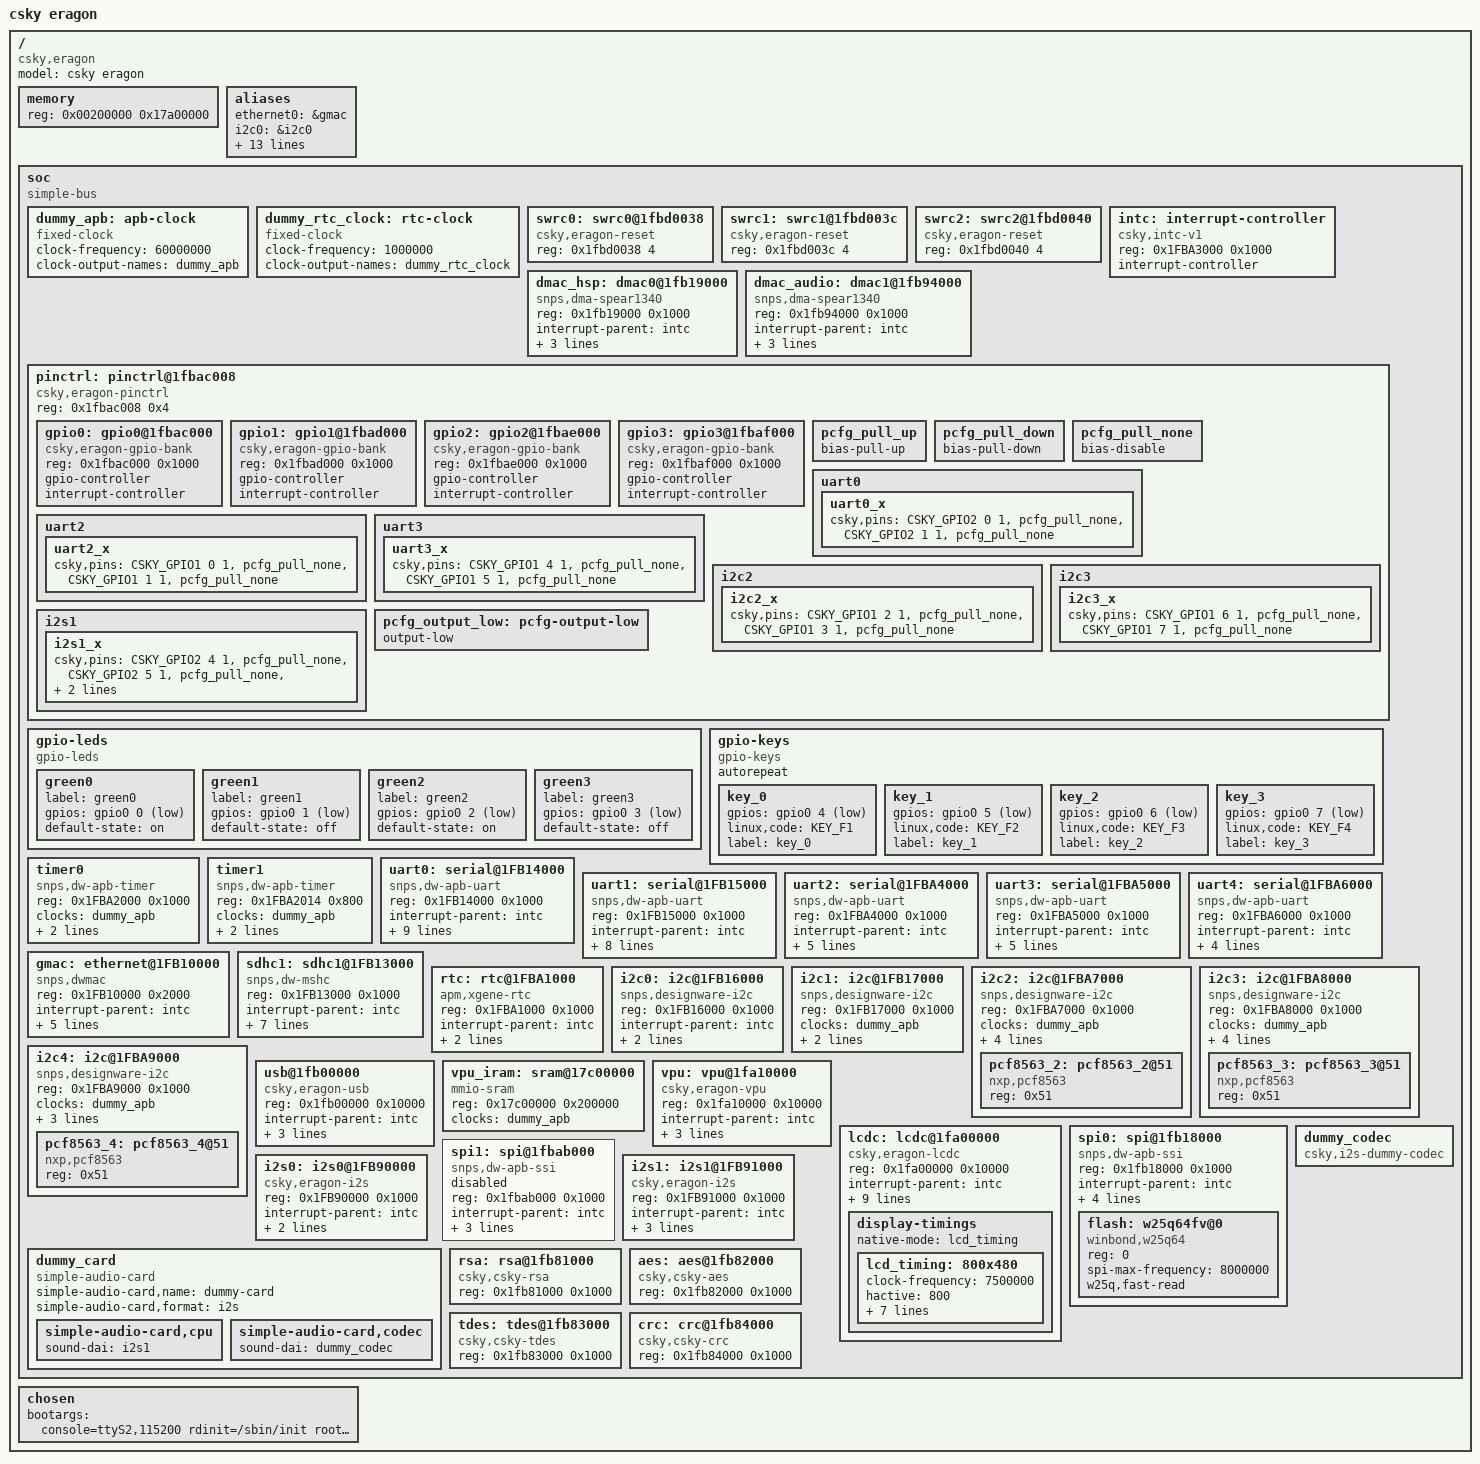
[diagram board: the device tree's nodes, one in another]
/dts-v1/;
#include <dt-bindings/interrupt-controller/irq.h>
#include <dt-bindings/gpio/gpio.h>
#include <dt-bindings/input/input.h>
#include "../../../../addons/drivers/pinctrl/pinctrl-csky.h"

/ {
	model = "csky eragon";
	compatible = "csky,eragon";
	#address-cells = <1>;
	#size-cells = <1>;

	memory {
		device_type = "memory";
		reg = <0x00200000 0x17a00000>;	// Reserve first 2MB for VPU work buf, last 2MB for iram
	};

	aliases {
		ethernet0 = &gmac;
		i2c0 = &i2c0;
		i2c1 = &i2c1;
		i2c2 = &i2c2;
		i2c3 = &i2c3;
		i2c4 = &i2c4;
		rtc0 = &rtc;
		rtc2 = &pcf8563_2;
		rtc3 = &pcf8563_3;
		rtc4 = &pcf8563_4;
		serial0 = &uart0;
		serial1 = &uart1;
		serial2 = &uart2;
		serial3 = &uart3;
		serial4 = &uart4;
	};

	soc {
		#address-cells = <1>;
		#size-cells = <1>;
		compatible = "simple-bus";
		ranges;

		dummy_apb: apb-clock {
			compatible = "fixed-clock";
			clock-frequency = <60000000>;
			clock-output-names = "dummy_apb";
			#clock-cells = <0>;
		};
		dummy_rtc_clock: rtc-clock {
			compatible = "fixed-clock";
			clock-frequency = <1000000>;
			clock-output-names = "dummy_rtc_clock";
			#clock-cells = <0>;
		};

		swrc0: swrc0@1fbd0038 {
			compatible = "csky,eragon-reset";
			reg = <0x1fbd0038 4>;
			#reset-cells = <1>;
		};

		swrc1: swrc1@1fbd003c {
			compatible = "csky,eragon-reset";
			reg = <0x1fbd003c 4>;
			#reset-cells = <1>;
		};

		swrc2: swrc2@1fbd0040 {
			compatible = "csky,eragon-reset";
			reg = <0x1fbd0040 4>;
			#reset-cells = <1>;
		};

		intc: interrupt-controller {
			compatible = "csky,intc-v1";
			reg = <0x1FBA3000 0x1000>;
			interrupt-controller;
			#interrupt-cells = <1>;
		};

		dmac_hsp: dmac0@1fb19000 {
			compatible = "snps,dma-spear1340";
			reg = <0x1fb19000 0x1000>;
			interrupt-parent = <&intc>;
			interrupts = <25>;
			clocks = <&dummy_apb>;
			clock-names = "hclk";
			#dma-cells = <3>;
			master-id = <0>;
		};

		dmac_audio: dmac1@1fb94000 {
			compatible = "snps,dma-spear1340";
			reg = <0x1fb94000 0x1000>;
			interrupt-parent = <&intc>;
			interrupts = <26>;
			clocks = <&dummy_apb>;
			clock-names = "hclk";
			#dma-cells = <3>;
			master-id = <1>;
		};

		pinctrl: pinctrl@1fbac008 {
			compatible = "csky,eragon-pinctrl";
			reg = <0x1fbac008 0x4>;

			#address-cells = <1>;
			#size-cells = <1>;
			ranges;

			gpio0: gpio0@1fbac000 {
				compatible = "csky,eragon-gpio-bank";
				reg = <0x1fbac000 0x1000>;
				/*clocks = <&cru PCLK_GPIO0>;*/

				gpio-controller;
				#gpio-cells = <2>;

				interrupt-controller;
				#interrupt-cells = <2>;
			};

			gpio1: gpio1@1fbad000 {
				compatible = "csky,eragon-gpio-bank";
				reg = <0x1fbad000 0x1000>;
				/*clocks = <&cru PCLK_GPIO1>;*/

				gpio-controller;
				#gpio-cells = <2>;

				interrupt-controller;
				#interrupt-cells = <2>;
			};

			gpio2: gpio2@1fbae000 {
				compatible = "csky,eragon-gpio-bank";
				reg = <0x1fbae000 0x1000>;
				/*clocks = <&cru PCLK_GPIO2>;*/

				gpio-controller;
				#gpio-cells = <2>;

				interrupt-controller;
				#interrupt-cells = <2>;
			};

			gpio3: gpio3@1fbaf000 {
				compatible = "csky,eragon-gpio-bank";
				reg = <0x1fbaf000 0x1000>;
				/*clocks = <&cru PCLK_GPIO3>;*/

				gpio-controller;
				#gpio-cells = <2>;

				interrupt-controller;
				#interrupt-cells = <2>;
			};

			pcfg_pull_up: pcfg_pull_up {
				bias-pull-up;
			};

			pcfg_pull_down: pcfg_pull_down {
				bias-pull-down;
			};

			pcfg_pull_none: pcfg_pull_none {
				bias-disable;
			};

			uart0 {
				uart0_x: uart0_x {
					csky,pins = <CSKY_GPIO2 0 1 &pcfg_pull_none>,
						    <CSKY_GPIO2 1 1 &pcfg_pull_none>;
				};
			};

			uart2 {
				uart2_x: uart2_x {
					csky,pins = <CSKY_GPIO1 0 1 &pcfg_pull_none>,
						    <CSKY_GPIO1 1 1 &pcfg_pull_none>;
				};
			};

			uart3 {
				uart3_x: uart3_x {
					csky,pins = <CSKY_GPIO1 4 1 &pcfg_pull_none>,
						    <CSKY_GPIO1 5 1 &pcfg_pull_none>;
				};
			};

			i2c2 {
				i2c2_x: i2c2_x {
					csky,pins = <CSKY_GPIO1 2 1 &pcfg_pull_none>,
						    <CSKY_GPIO1 3 1 &pcfg_pull_none>;
				};
			};

			i2c3 {
				i2c3_x: i2c3_x {
					csky,pins = <CSKY_GPIO1 6 1 &pcfg_pull_none>,
						    <CSKY_GPIO1 7 1 &pcfg_pull_none>;
				};
			};

			i2s1 {
				i2s1_x: i2s1_x {
					csky,pins = <CSKY_GPIO2 4 1 &pcfg_pull_none>,
						    <CSKY_GPIO2 5 1 &pcfg_pull_none>,
						    <CSKY_GPIO2 6 1 &pcfg_pull_none>,
						    <CSKY_GPIO2 7 1 &pcfg_pull_none>;
				};
			};
		};

		gpio-leds {
			compatible = "gpio-leds";

			green0 {
				label = "green0";
				gpios = <&gpio0 0 GPIO_ACTIVE_LOW>;
				default-state = "on";
			};

			green1 {
				label = "green1";
				gpios = <&gpio0 1 GPIO_ACTIVE_LOW>;
				default-state = "off";
			};

			green2 {
				label = "green2";
				gpios = <&gpio0 2 GPIO_ACTIVE_LOW>;
				default-state = "on";
			};

			green3 {
				label = "green3";
				gpios = <&gpio0 3 GPIO_ACTIVE_LOW>;
				default-state = "off";
			};
		};

		gpio-keys {
			compatible = "gpio-keys";
			autorepeat;

			key_0 {
				gpios = <&gpio0 4 GPIO_ACTIVE_LOW>;
				linux,code = <KEY_F1>;
				label = "key_0";
			};

			key_1 {
				gpios = <&gpio0 5 GPIO_ACTIVE_LOW>;
				linux,code = <KEY_F2>;
				label = "key_1";
			};

			key_2 {
				gpios = <&gpio0 6 GPIO_ACTIVE_LOW>;
				linux,code = <KEY_F3>;
				label = "key_2";
			};

			key_3 {
				gpios = <&gpio0 7 GPIO_ACTIVE_LOW>;
				linux,code = <KEY_F4>;
				label = "key_3";
			};
		};

		/* clockevent */
		timer0 {
			compatible = "snps,dw-apb-timer";
			reg = <0x1FBA2000 0x1000>;
			clocks = <&dummy_apb>;
			clock-names = "timer";
			interrupts = <4>;
			interrupt-parent = <&intc>;
		};

		/* clocksource */
		timer1 {
			compatible = "snps,dw-apb-timer";
			reg = <0x1FBA2014 0x800>;
			clocks = <&dummy_apb>;
			clock-names = "timer";
			interrupts = <5>;
			interrupt-parent = <&intc>;
		};

		uart0: serial@1FB14000 {
			compatible = "snps,dw-apb-uart";
			reg = <0x1FB14000 0x1000>;
			interrupt-parent = <&intc>;
			interrupts = <9>;
			clocks = <&dummy_apb>;
			clock-names = "baudclk";
			reg-shift = <2>;
			reg-io-width = <1>;
			pinctrl-names = "default";
			pinctrl-0 = <&uart0_x>;
			fifo-size = <16>;
			/*
			 * rx-trigger-level:
			 *     0 - 1 character
			 *     1 - 1/4 full
			 *     2 - 1/2 full
			 *     3 - (fifo size - 2)
			 */
			rx-trigger-level = <2>;
			dma-enable = <0>; /* 1-enable uart dma, 0-disable */
			dmas = <&dmac_hsp 0 0 1>, <&dmac_hsp 1 0 1>;
			dma-names = "rx", "tx";
		};

		uart1: serial@1FB15000 {
			compatible = "snps,dw-apb-uart";
			reg = <0x1FB15000 0x1000>;
			interrupt-parent = <&intc>;
			interrupts = <10>;
			clocks = <&dummy_apb>;
			clock-names = "baudclk";
			reg-shift = <2>;
			reg-io-width = <1>;
			fifo-size = <16>;
			/*
			 * rx-trigger-level:
			 *     0 - 1 character
			 *     1 - 1/4 full
			 *     2 - 1/2 full
			 *     3 - (fifo size - 2)
			 */
			rx-trigger-level = <2>;
			dma-enable = <0>; /* 1-enable uart dma, 0-disable */
			dmas = <&dmac_hsp 2 0 1>, <&dmac_hsp 3 0 1>;
			dma-names = "rx", "tx";
		};

		uart2: serial@1FBA4000 {
			compatible = "snps,dw-apb-uart";
			reg = <0x1FBA4000 0x1000>;
			interrupt-parent = <&intc>;
			interrupts = <11>;
			clocks = <&dummy_apb>;
			clock-names = "baudclk";
			reg-shift = <2>;
			reg-io-width = <1>;
			pinctrl-names = "default";
			pinctrl-0 = <&uart2_x>;
		};

		uart3: serial@1FBA5000 {
			compatible = "snps,dw-apb-uart";
			reg = <0x1FBA5000 0x1000>;
			interrupt-parent = <&intc>;
			interrupts = <12>;
			clocks = <&dummy_apb>;
			clock-names = "baudclk";
			reg-shift = <2>;
			reg-io-width = <1>;
			pinctrl-names = "default";
			pinctrl-0 = <&uart3_x>;
		};

		uart4: serial@1FBA6000 {
			compatible = "snps,dw-apb-uart";
			reg = <0x1FBA6000 0x1000>;
			interrupt-parent = <&intc>;
			interrupts = <13>;
			clocks = <&dummy_apb>;
			clock-names = "baudclk";
			reg-shift = <2>;
			reg-io-width = <1>;
		};

		gmac: ethernet@1FB10000 {
			compatible = "snps,dwmac";
			reg = <0x1FB10000 0x2000>;
			interrupt-parent = <&intc>;
			interrupts = <34>;
			interrupt-names = "macirq";
			clocks = <&dummy_apb>;
			clock-names = "stmmaceth";
			phy-mode = "mii";
			snps,pbl = <32>;
			snps,fixed-burst;
		};
/*
		sdhc0: sdhc0@1FB12000 {
			#address-cells = <1>;
			#size-cells = <0>;
			compatible = "snps,dw-mshc";
			reg = <0x1FB12000 0x1000>;
			interrupt-parent = <&intc>;
			interrupts = <32>;
			clocks = <&dummy_apb>, <&dummy_apb>;
			clock-names = "ciu", "biu";
			num-slots = <0x1>;
			card-detect-delay = <200>;
			cap-mmc-highspeed;
			bus-width = <4>;

			mmccard: mmccard@0 {
				reg = <0>;
				compatible = "mmc-card";
				broken-hpi;
			};
		};
*/
		sdhc1: sdhc1@1FB13000 {
			#address-cells = <1>;
			#size-cells = <0>;
			compatible = "snps,dw-mshc";
			reg = <0x1FB13000 0x1000>;
			interrupt-parent = <&intc>;
			interrupts = <33>;
			clocks = <&dummy_apb>, <&dummy_apb>;
			clock-names = "ciu", "biu";
			num-slots = <0x1>;
			// fifo-depth = <32>;
			card-detect-delay = <200>;
			cap-mmc-highspeed;
			non-removable;
			bus-width = <0x8>;
			/*
			emmc: emmc@0 {
				reg = <0>;
				compatible = "mmc-card";
				broken-hpi;
			};
			*/
		};

		rtc: rtc@1FBA1000 {
			compatible = "apm,xgene-rtc";
			reg = <0x1FBA1000 0x1000>;
			interrupt-parent = <&intc>;
			interrupts = <8>;
			clocks = <&dummy_rtc_clock>;
		};

		i2c0: i2c@1FB16000 {
			#address-cells = <1>;
			#size-cells = <0>;
			compatible = "snps,designware-i2c";
			reg = <0x1FB16000 0x1000>;
			interrupt-parent = <&intc>;
			interrupts = <16>;
			clocks = <&dummy_apb>;
		};

		i2c1: i2c@1FB17000 {
			#address-cells = <1>;
			#size-cells = <0>;
			compatible = "snps,designware-i2c";
			reg = <0x1FB17000 0x1000>;
			clocks = <&dummy_apb>;
			interrupt-parent = <&intc>;
			interrupts = <17>;
		};

		i2c2: i2c@1FBA7000 {
			#address-cells = <1>;
			#size-cells = <0>;
			compatible = "snps,designware-i2c";
			reg = <0x1FBA7000 0x1000>;
			clocks = <&dummy_apb>;
			interrupt-parent = <&intc>;
			interrupts = <18>;
			clock-frequency = <100000>;
			pinctrl-names = "default";
			pinctrl-0 = <&i2c2_x>;

			pcf8563_2: pcf8563_2@51 {
				compatible = "nxp,pcf8563";
				reg = <0x51>;
			};
		};

		i2c3: i2c@1FBA8000 {
			#address-cells = <1>;
			#size-cells = <0>;
			compatible = "snps,designware-i2c";
			reg = <0x1FBA8000 0x1000>;
			clocks = <&dummy_apb>;
			interrupt-parent = <&intc>;
			interrupts = <19>;
			clock-frequency = <100000>;
			pinctrl-names = "default";
			pinctrl-0 = <&i2c3_x>;

			pcf8563_3: pcf8563_3@51 {
				compatible = "nxp,pcf8563";
				reg = <0x51>;
			};
		};

		i2c4: i2c@1FBA9000 {
			#address-cells = <1>;
			#size-cells = <0>;
			compatible = "snps,designware-i2c";
			reg = <0x1FBA9000 0x1000>;
			clocks = <&dummy_apb>;
			interrupt-parent = <&intc>;
			interrupts = <20>;
			clock-frequency = <100000>;

			pcf8563_4: pcf8563_4@51 {
				compatible = "nxp,pcf8563";
				reg = <0x51>;
			};
		};

		usb@1fb00000 {
			compatible = "csky,eragon-usb", "snps,dwc2";
			reg = <0x1fb00000 0x10000>;
			interrupt-parent = <&intc>;
			interrupts = <35>;
			clocks = <&dummy_apb>;
			clock-names = "otg";
			dr_mode = "host";
		};

		vpu_iram: sram@17c00000 {
			compatible = "mmio-sram";
			reg = <0x17c00000 0x200000>;
			clocks = <&dummy_apb>;
		};

		vpu: vpu@1fa10000 {
			compatible = "csky,eragon-vpu", "cnm,coda7541";
			reg = <0x1fa10000 0x10000>;
			interrupt-parent = <&intc>;
			interrupts = <41>;
			clocks = <&dummy_apb>, <&dummy_apb>;
			clock-names = "ahb", "per";
			iram = <&vpu_iram>;
		};

		lcdc: lcdc@1fa00000 {
			compatible = "csky,eragon-lcdc";
			reg = <0x1fa00000 0x10000>;
			interrupt-parent = <&intc>;
			interrupts = <40>;
			clocks = <&dummy_apb>;
			clock-names = "lcdc";
			resets = <&swrc1 14>; /* SWRC1[14]: SW_IP_LCDC_RST */
			bits-per-pixel = <32>;
			pixel-clock-source = <0>; /* 0=HCLK, 1=external clock */
			pcd = <1>; /* pixel clock divider. f=HCLK/2(pcd+1) */
			hsync-pulse-pol = <1>; /* HSYNC pulse polarity. 1=active low */
			vsync-pulse-pol = <1>; /* VSYNC pulse polarity. 1=active low */
			pixel-clock-pol = <0>; /* 0=data is driven on the rising edge */

			display-timings {
				native-mode = <&lcd_timing>;
				lcd_timing: 800x480 {
					clock-frequency = <7500000>;
					hactive = <800>;
					vactive = <480>;
					hfront-porch = <82>;
					hback-porch = <43>;
					hsync-len = <3>;
					vback-porch = <20>;
					vfront-porch = <22>;
					vsync-len = <3>;
				};
			};
		};

		spi0: spi@1fb18000 {
			compatible = "snps,dw-apb-ssi";
			#address-cells = <1>;
			#size-cells = <0>;
			reg = <0x1fb18000 0x1000>;
			interrupt-parent = <&intc>;
			interrupts = <14>;
			num-cs = <4>;

			cs-gpios = <&gpio3 1 GPIO_ACTIVE_HIGH>,
				   <&gpio3 2 GPIO_ACTIVE_HIGH>,
				   <&gpio3 3 GPIO_ACTIVE_HIGH>,
				   <&gpio3 4 GPIO_ACTIVE_HIGH>;

			clocks = <&dummy_apb>;

			flash: w25q64fv@0 {
				#address-cells = <1>;
				#size-cells = <1>;
				compatible = "winbond,w25q64", "jedec,spi-nor";
				reg = <0>;
				spi-max-frequency = <8000000>;
				w25q,fast-read;
			};
		};

		spi1: spi@1fbab000 {
			compatible = "snps,dw-apb-ssi";
			#address-cells = <1>;
			#size-cells = <0>;
			reg = <0x1fbab000 0x1000>;
			interrupt-parent = <&intc>;
			interrupts = <15>;
			num-cs = <4>;
			clocks = <&dummy_apb>;
			status = "disabled";
		};

		i2s0: i2s0@1FB90000 {
			compatible = "csky,eragon-i2s";
			reg = <0x1FB90000 0x1000>;
			interrupt-parent = <&intc>;
			interrupts = <36>;
			dmas = <&dmac_audio 0 1 0>, <&dmac_audio 1 1 0>;
			dma-names = "rx", "tx";
			#sound-dai-cells = <0>;
		};

		i2s1: i2s1@1FB91000 {
			compatible = "csky,eragon-i2s";
			reg = <0x1FB91000 0x1000>;
			interrupt-parent = <&intc>;
			interrupts = <37>;
			dmas = <&dmac_audio 2 1 0>, <&dmac_audio 3 1 0>;
			dma-names = "rx", "tx";
			#sound-dai-cells = <0>;
			pinctrl-names = "default";
			pinctrl-0 = <&i2s1_x>;
		};

		dummy_codec: dummy_codec {
			compatible = "csky,i2s-dummy-codec";
			#sound-dai-cells = <0>;
		};

		dummy_card {
			compatible = "simple-audio-card";
			simple-audio-card,name = "dummy-card";
			simple-audio-card,format = "i2s";

			simple-audio-card,cpu {
				sound-dai = <&i2s1>;
			};

			simple-audio-card,codec {
				sound-dai = <&dummy_codec>;
			};
		};

		rsa: rsa@1fb81000 {
			compatible = "csky,csky-rsa";
			reg = <0x1fb81000 0x1000>;
		};

		aes: aes@1fb82000 {
			compatible = "csky,csky-aes";
			reg = <0x1fb82000 0x1000>;
		};

		tdes: tdes@1fb83000 {
			compatible = "csky,csky-tdes";
			reg = <0x1fb83000 0x1000>;
		};

		crc: crc@1fb84000 {
			compatible = "csky,csky-crc";
			reg = <0x1fb84000 0x1000>;
		};

	};

	chosen {
		// bootargs = "console=ttyS2,115200 init=/sbin/init root=/dev/nfs rw nfsroot=172.16.28.184:/home/rtos_nfs/br/rootfs,v3,tcp,nolock ip=172.16.150.100::172.16.150.254:255.255.255.0";
		bootargs = "console=ttyS2,115200 rdinit=/sbin/init root=/dev/ram0";
	};
};

&pinctrl {
	pcfg_output_low: pcfg-output-low {
		output-low;
	};
};

